# fcr_me30 register map
Registers are read-write, no defined reset value unless marked. A register's access mark holds for its fields unless they carry their own. Offsets are from the block's base; lines under a group give offsets from that group; [hi:lo] are bit positions; {n}, {i} and the like mark numbered series; 'fields as' and 'values as' point back to an identical list; <NAME> marks a mode.

## Memory map
0x40000800 FCR size 0x400 — Function Control Register.

## FCR — Function Control Register.
Base 0x40000800
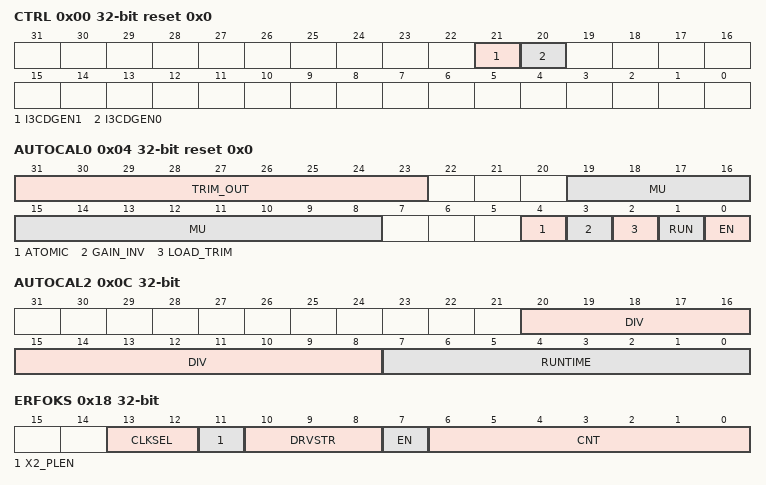
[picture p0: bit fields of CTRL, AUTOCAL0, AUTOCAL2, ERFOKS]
0x00 CTRL reset 0x0 — Function Control 0 Register.
  [21] I3CDGEN1 — I3C SCL Deglitch Bypass. When set, the SCL deglitch filter is bypassed.
    0=active (Deglitch filter active (not bypassed).); 1=bypass (Deglitch filter bypassed.)
  [20] I3CDGEN0 — I3C SDA Deglitch Bypass. When set, the SDA deglitch filter is bypassed.
    values as I3CDGEN1
0x04 AUTOCAL0 reset 0x0 — Automatic Calibration 0 Register.
  [31:23] TRIM_OUT ro — IPO Auto Calibration Trim output value (read-only result).
  [19:8] MU — MU value.
  [4] ATOMIC — Atomic calibration trigger. Write 1 to start a single-shot calibration; self-clearing.
    0=Normal (non-atomic) mode; 1=Atomic calibration in progress (self-clears on completion)
  [3] GAIN_INV — Invert Gain. When set, the calibration gain is inverted.
    0=Normal gain (not inverted); 1=Inverted gain
  [2] LOAD_TRIM
  [1] RUN — Autocalibration Run.
    0=not (Not Running.); 1=run (Running.)
  [0] EN — Auto-calibration Enable.
    0=dis (Disabled.); 1=en (Enabled.)
0x08 AUTOCAL1 — Automatic Calibration 1 Register.
  [8:0] INIT_TRIM — IPO Trim Automatic Calibration Initial Trim.
0x0C AUTOCAL2 — Automatic Calibration 2 Register.
  [20:8] DIV — IPO Trim Automatic Calibration Divide Factor.
  [7:0] RUNTIME — IPO Trim Autocal Run Time
0x18 ERFOKS — ERFO Kick Start Register.
  [13:12] CLKSEL — Kick Start Clock Select for ERFO
    0=NO_CLK (No kick start clock.); 3=IPO
  [11] X2_PLEN — ERFO Kick Start Enable Double Pulse Length.
  [10:8] DRVSTR — Kick Start ERFO Drive Strength.
  [7] EN — Kick Start ERFO Enable.
  [6:0] CNT — Kick Start ERFO Counter.
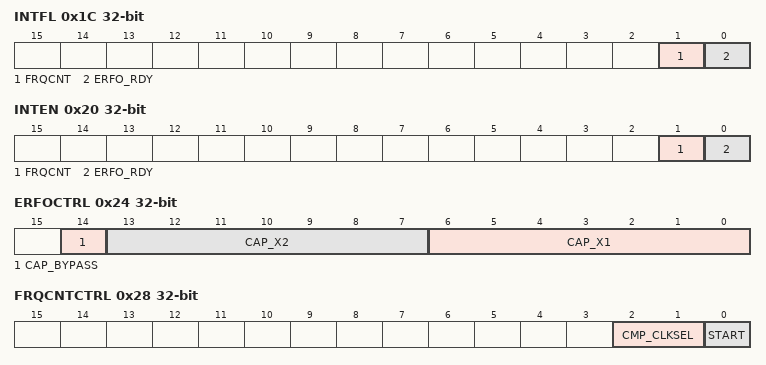
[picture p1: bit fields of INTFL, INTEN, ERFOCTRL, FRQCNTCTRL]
0x1C INTFL — Interrupt Flag Register.
  [1] FRQCNT write-1-clears — Frequency Counter Interrupt Flag. Write 1 to clear.
  [0] ERFO_RDY write-1-clears — ERFO Ready. Write 1 to clear.
0x20 INTEN — Interrupt Enable Register.
  [1] FRQCNT — Frequency Counter Interrupt Enable.
  [0] ERFO_RDY — ERFO Ready Interrupt Enable.
0x24 ERFOCTRL — ERFO Control Register.
  [14] CAP_BYPASS — Bypass (disable) load capacitors.
  [13:7] CAP_X2 — Load capacitor tuning bit for X2.
  [6:0] CAP_X1 — Load capacitor tuning bit for X1.
0x28 FRQCNTCTRL — Frequency Counter Control Register.
  [2:1] CMP_CLKSEL — Compared Clock Select.
    0=RTC (32kHz RTC (ERTCO).); 1=RTC_ALT (32kHz RTC (alternate path, same 32kHz source as value 0).); 2=EXT_GPIO (External GPIO.); 3=INRO
  [0] START — Start Compare. Write 1 to start frequency count; self-clearing when measurement completes.
0x2C FRQCNTCMP — Frequency Counter Compared Target Register.
  [13:0] TARGET — Compared Clock Target.
0x30 REFCLK ro — Reference Clock Result Register.
  [19:0] RESULT — Reference Clock Result.
0x34 CMPCLK ro — Compared Clock Result Register.
  [13:0] RESULT — Compared Clock Result.
